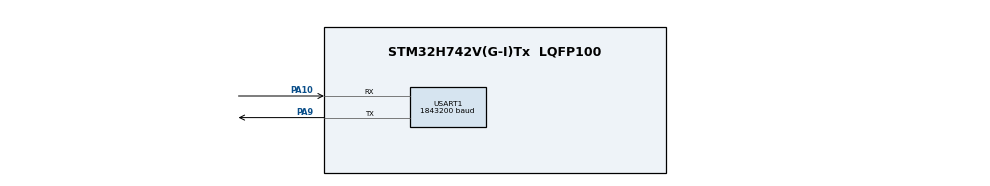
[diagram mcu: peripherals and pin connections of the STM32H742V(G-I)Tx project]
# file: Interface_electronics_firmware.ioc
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CORTEX_M7.default_mode_Activation=1
Mcu.Family=STM32H7
Mcu.Name=STM32H742V(G-I)Tx
Mcu.Package=LQFP100
NVIC.PriorityGroup=NVIC_PRIORITYGROUP_4
NVIC.TIM3_IRQn=true\:0\:0\:false\:false\:true\:true\:true\:true
NVIC.USART1_IRQn=true\:0\:0\:false\:false\:true\:true\:true\:true
PA10.Mode=Asynchronous
PA10.Signal=USART1_RX
PA9.Mode=Asynchronous
PA9.Signal=USART1_TX
ProjectManager.HeapSize=0x200
ProjectManager.StackSize=0x400
ProjectManager.TargetToolchain=STM32CubeIDE
RCC.ADCFreq_Value=129000000
RCC.APB1Freq_Value=120000000
RCC.APB2Freq_Value=120000000
RCC.APB3Freq_Value=120000000
RCC.APB4Freq_Value=120000000
RCC.CortexFreq_Value=480000000
RCC.D1PPRE=RCC_APB3_DIV2
RCC.D2PPRE1=RCC_APB1_DIV2
RCC.D2PPRE2=RCC_APB2_DIV2
RCC.D3PPRE=RCC_APB4_DIV2
RCC.DIVM1=4
RCC.DIVN1=60
RCC.HCLKFreq_Value=240000000
RCC.HPRE=RCC_HCLK_DIV2
RCC.PLL2FRACN=0
RCC.PLL3FRACN=0
RCC.PLLFRACN=0
RCC.SYSCLKFreq_VALUE=480000000
RCC.SYSCLKSource=RCC_SYSCLKSOURCE_PLLCLK
RCC.USBFreq_Value=480000000
TIM2.Prescaler=479
TIM3.Period=499
TIM3.Prescaler=479
USART1.BaudRate=1843200
USART1.VirtualMode-Asynchronous=VM_ASYNC
VP_MEMORYMAP_VS_MEMORYMAP.Mode=CurAppReg
VP_TIM2_VS_ClockSourceINT.Mode=Internal
VP_TIM3_VS_ClockSourceINT.Mode=Internal
board=custom

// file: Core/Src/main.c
/* USER CODE BEGIN Header */
/**
  ******************************************************************************
  * @file           : main.c
  * @brief          : Main program body
  ******************************************************************************
  * @attention
  *
  * Copyright (c) 2025 STMicroelectronics.
  * All rights reserved.
  *
  * This software is licensed under terms that can be found in the LICENSE file
  * in the root directory of this software component.
  * If no LICENSE file comes with this software, it is provided AS-IS.
  *
  ******************************************************************************
  */
/* USER CODE END Header */
#include "main.h"

/* USER CODE BEGIN Includes */
#include <string.h>
#include <stdlib.h>
/* USER CODE END Includes */

/* USER CODE BEGIN PTD */
#define PACKET_SIZE 8
typedef struct __attribute__((packed)) {
    uint8_t  header[3];      // 0x3C, 0x3E, 0x00
    uint32_t timestamp_us;   // from TIM2
    uint16_t seq;            // incremental sequence
    int16_t  ch[PACKET_SIZE];         // 64 channels (dummy data here)
} SamplePacket;

/* USER CODE END PTD */

TIM_HandleTypeDef htim2;
TIM_HandleTypeDef htim3;

UART_HandleTypeDef huart1;

/* USER CODE BEGIN PV */
volatile uint8_t start_sending = 0;
volatile uint16_t seq = 0;

char rx_buffer[32];
uint8_t rx_index = 0;
uint8_t rx_byte;
/* USER CODE END PV */

void SystemClock_Config(void);
static void MPU_Config(void);
static void MX_GPIO_Init(void);
static void MX_USART1_UART_Init(void);
static void MX_TIM2_Init(void);
static void MX_TIM3_Init(void);

int main(void)
{

  /* MPU Configuration--------------------------------------------------------*/
  MPU_Config();

  /* MCU Configuration--------------------------------------------------------*/

  /* Reset of all peripherals, Initializes the Flash interface and the Systick. */
  HAL_Init();

  /* Configure the system clock */
  SystemClock_Config();

  /* Initialize all configured peripherals */
  MX_GPIO_Init();
  MX_USART1_UART_Init();
  MX_TIM2_Init();
  MX_TIM3_Init();
  /* USER CODE BEGIN 2 */
  HAL_TIM_Base_Start(&htim2);              // TIM2 free running at 1 MHz
  HAL_TIM_Base_Start_IT(&htim3);           // TIM3 generates sample every 0.5 ms
  HAL_UART_Receive_IT(&huart1, &rx_byte, 1);
  /* USER CODE END 2 */

  /* Infinite loop */
  while (1)
  {

  }
}

void SystemClock_Config(void)
{
  RCC_OscInitTypeDef RCC_OscInitStruct = {0};
  RCC_ClkInitTypeDef RCC_ClkInitStruct = {0};

  /** Supply configuration update enable
  */
  HAL_PWREx_ConfigSupply(PWR_LDO_SUPPLY);

  /** Configure the main internal regulator output voltage
  */
  __HAL_PWR_VOLTAGESCALING_CONFIG(PWR_REGULATOR_VOLTAGE_SCALE0);

  while(!__HAL_PWR_GET_FLAG(PWR_FLAG_VOSRDY)) {}

  /** Initializes the RCC Oscillators according to the specified parameters
  * in the RCC_OscInitTypeDef structure.
  */
  RCC_OscInitStruct.OscillatorType = RCC_OSCILLATORTYPE_HSI;
  RCC_OscInitStruct.HSIState = RCC_HSI_DIV1;
  RCC_OscInitStruct.HSICalibrationValue = RCC_HSICALIBRATION_DEFAULT;
  RCC_OscInitStruct.PLL.PLLState = RCC_PLL_ON;
  RCC_OscInitStruct.PLL.PLLSource = RCC_PLLSOURCE_HSI;
  RCC_OscInitStruct.PLL.PLLM = 4;
  RCC_OscInitStruct.PLL.PLLN = 60;
  RCC_OscInitStruct.PLL.PLLP = 2;
  RCC_OscInitStruct.PLL.PLLQ = 2;
  RCC_OscInitStruct.PLL.PLLR = 2;
  RCC_OscInitStruct.PLL.PLLRGE = RCC_PLL1VCIRANGE_3;
  RCC_OscInitStruct.PLL.PLLVCOSEL = RCC_PLL1VCOWIDE;
  RCC_OscInitStruct.PLL.PLLFRACN = 0;
  if (HAL_RCC_OscConfig(&RCC_OscInitStruct) != HAL_OK)
  {
    Error_Handler();
  }

  /** Initializes the CPU, AHB and APB buses clocks
  */
  RCC_ClkInitStruct.ClockType = RCC_CLOCKTYPE_HCLK|RCC_CLOCKTYPE_SYSCLK
                              |RCC_CLOCKTYPE_PCLK1|RCC_CLOCKTYPE_PCLK2
                              |RCC_CLOCKTYPE_D3PCLK1|RCC_CLOCKTYPE_D1PCLK1;
  RCC_ClkInitStruct.SYSCLKSource = RCC_SYSCLKSOURCE_PLLCLK;
  RCC_ClkInitStruct.SYSCLKDivider = RCC_SYSCLK_DIV1;
  RCC_ClkInitStruct.AHBCLKDivider = RCC_HCLK_DIV2;
  RCC_ClkInitStruct.APB3CLKDivider = RCC_APB3_DIV2;
  RCC_ClkInitStruct.APB1CLKDivider = RCC_APB1_DIV2;
  RCC_ClkInitStruct.APB2CLKDivider = RCC_APB2_DIV2;
  RCC_ClkInitStruct.APB4CLKDivider = RCC_APB4_DIV2;

  if (HAL_RCC_ClockConfig(&RCC_ClkInitStruct, FLASH_LATENCY_4) != HAL_OK)
  {
    Error_Handler();
  }
}

static void MX_TIM2_Init(void)
{

  TIM_ClockConfigTypeDef sClockSourceConfig = {0};
  TIM_MasterConfigTypeDef sMasterConfig = {0};

  htim2.Instance = TIM2;
  htim2.Init.Prescaler = 479;
  htim2.Init.CounterMode = TIM_COUNTERMODE_UP;
  htim2.Init.Period = 4294967295;
  htim2.Init.ClockDivision = TIM_CLOCKDIVISION_DIV1;
  htim2.Init.AutoReloadPreload = TIM_AUTORELOAD_PRELOAD_DISABLE;
  if (HAL_TIM_Base_Init(&htim2) != HAL_OK)
  {
    Error_Handler();
  }
  sClockSourceConfig.ClockSource = TIM_CLOCKSOURCE_INTERNAL;
  if (HAL_TIM_ConfigClockSource(&htim2, &sClockSourceConfig) != HAL_OK)
  {
    Error_Handler();
  }
  sMasterConfig.MasterOutputTrigger = TIM_TRGO_RESET;
  sMasterConfig.MasterSlaveMode = TIM_MASTERSLAVEMODE_DISABLE;
  if (HAL_TIMEx_MasterConfigSynchronization(&htim2, &sMasterConfig) != HAL_OK)
  {
    Error_Handler();
  }

}

static void MX_TIM3_Init(void)
{

  TIM_ClockConfigTypeDef sClockSourceConfig = {0};
  TIM_MasterConfigTypeDef sMasterConfig = {0};

  htim3.Instance = TIM3;
  htim3.Init.Prescaler = 479;
  htim3.Init.CounterMode = TIM_COUNTERMODE_UP;
  htim3.Init.Period = 499;
  htim3.Init.ClockDivision = TIM_CLOCKDIVISION_DIV1;
  htim3.Init.AutoReloadPreload = TIM_AUTORELOAD_PRELOAD_DISABLE;
  if (HAL_TIM_Base_Init(&htim3) != HAL_OK)
  {
    Error_Handler();
  }
  sClockSourceConfig.ClockSource = TIM_CLOCKSOURCE_INTERNAL;
  if (HAL_TIM_ConfigClockSource(&htim3, &sClockSourceConfig) != HAL_OK)
  {
    Error_Handler();
  }
  sMasterConfig.MasterOutputTrigger = TIM_TRGO_RESET;
  sMasterConfig.MasterSlaveMode = TIM_MASTERSLAVEMODE_DISABLE;
  if (HAL_TIMEx_MasterConfigSynchronization(&htim3, &sMasterConfig) != HAL_OK)
  {
    Error_Handler();
  }

}

static void MX_USART1_UART_Init(void)
{

  huart1.Instance = USART1;
  huart1.Init.BaudRate = 1000000;
  huart1.Init.WordLength = UART_WORDLENGTH_8B;
  huart1.Init.StopBits = UART_STOPBITS_1;
  huart1.Init.Parity = UART_PARITY_NONE;
  huart1.Init.Mode = UART_MODE_TX_RX;
  huart1.Init.HwFlowCtl = UART_HWCONTROL_NONE;
  huart1.Init.OverSampling = UART_OVERSAMPLING_16;
  huart1.Init.OneBitSampling = UART_ONE_BIT_SAMPLE_DISABLE;
  huart1.Init.ClockPrescaler = UART_PRESCALER_DIV1;
  huart1.AdvancedInit.AdvFeatureInit = UART_ADVFEATURE_NO_INIT;
  if (HAL_UART_Init(&huart1) != HAL_OK)
  {
    Error_Handler();
  }
  if (HAL_UARTEx_SetTxFifoThreshold(&huart1, UART_TXFIFO_THRESHOLD_1_8) != HAL_OK)
  {
    Error_Handler();
  }
  if (HAL_UARTEx_SetRxFifoThreshold(&huart1, UART_RXFIFO_THRESHOLD_1_8) != HAL_OK)
  {
    Error_Handler();
  }
  if (HAL_UARTEx_DisableFifoMode(&huart1) != HAL_OK)
  {
    Error_Handler();
  }

}

static void MX_GPIO_Init(void)
{
  /* USER CODE BEGIN MX_GPIO_Init_1 */
	GPIO_InitTypeDef GPIO_InitStruct = {0};
  /* USER CODE END MX_GPIO_Init_1 */

  /* GPIO Ports Clock Enable */
  __HAL_RCC_GPIOA_CLK_ENABLE();

  /* USER CODE BEGIN MX_GPIO_Init_2 */
  GPIO_InitStruct.Pin = GPIO_PIN_9 | GPIO_PIN_10;
  GPIO_InitStruct.Mode = GPIO_MODE_AF_PP;
  GPIO_InitStruct.Pull = GPIO_NOPULL;
  GPIO_InitStruct.Speed = GPIO_SPEED_FREQ_VERY_HIGH;
  GPIO_InitStruct.Alternate = GPIO_AF7_USART1;
  HAL_GPIO_Init(GPIOA, &GPIO_InitStruct);
  /* USER CODE END MX_GPIO_Init_2 */
}

/* USER CODE BEGIN 4 */
void HAL_TIM_PeriodElapsedCallback(TIM_HandleTypeDef *htim)
{
    if (htim->Instance != TIM3) return;  // TIM3 = 0.5 ms sampler
    if (!start_sending) return;

    SamplePacket pkt;

    // Header
    pkt.header[0] = 0x3C;
    pkt.header[1] = 0x3E;
    pkt.header[2] = 0x00;

    // Timestamp (µs)
    pkt.timestamp_us = __HAL_TIM_GET_COUNTER(&htim2);

    // Sequence
    pkt.seq = seq++;

    // Dummy channels (replace with your sensors)
    for (int i = 0; i < PACKET_SIZE; i++)
        pkt.ch[i] = i * 100;

    // Send packet
    HAL_UART_Transmit(&huart1, (uint8_t*)&pkt, sizeof(pkt), HAL_MAX_DELAY);
}

void HAL_UART_RxCpltCallback(UART_HandleTypeDef *huart)
{
    if (huart->Instance != USART1)
        return;

    if (rx_byte != '\r' && rx_byte != '\n' && rx_index < sizeof(rx_buffer)-1)
    {
        rx_buffer[rx_index++] = rx_byte;
    }
    else
    {
        rx_buffer[rx_index] = '\0';

        if (strcmp(rx_buffer, "numx,all") == 0)
        {
            start_sending = 1;    // start streaming
            seq = 0;
        }
        else if (strcmp(rx_buffer, "stop") == 0)
        {
            start_sending = 0;    // stop streaming
        }

        rx_index = 0;
    }

    HAL_UART_Receive_IT(&huart1, &rx_byte, 1);

}
/* USER CODE END 4 */

 /* MPU Configuration */

void MPU_Config(void)
{
  MPU_Region_InitTypeDef MPU_InitStruct = {0};

  /* Disables the MPU */
  HAL_MPU_Disable();

  /** Initializes and configures the Region and the memory to be protected
  */
  MPU_InitStruct.Enable = MPU_REGION_ENABLE;
  MPU_InitStruct.Number = MPU_REGION_NUMBER0;
  MPU_InitStruct.BaseAddress = 0x0;
  MPU_InitStruct.Size = MPU_REGION_SIZE_4GB;
  MPU_InitStruct.SubRegionDisable = 0x87;
  MPU_InitStruct.TypeExtField = MPU_TEX_LEVEL0;
  MPU_InitStruct.AccessPermission = MPU_REGION_NO_ACCESS;
  MPU_InitStruct.DisableExec = MPU_INSTRUCTION_ACCESS_DISABLE;
  MPU_InitStruct.IsShareable = MPU_ACCESS_SHAREABLE;
  MPU_InitStruct.IsCacheable = MPU_ACCESS_NOT_CACHEABLE;
  MPU_InitStruct.IsBufferable = MPU_ACCESS_NOT_BUFFERABLE;

  HAL_MPU_ConfigRegion(&MPU_InitStruct);
  /* Enables the MPU */
  HAL_MPU_Enable(MPU_PRIVILEGED_DEFAULT);

}

void Error_Handler(void)
{
  __disable_irq();
  while (1)
  {
  }
}
